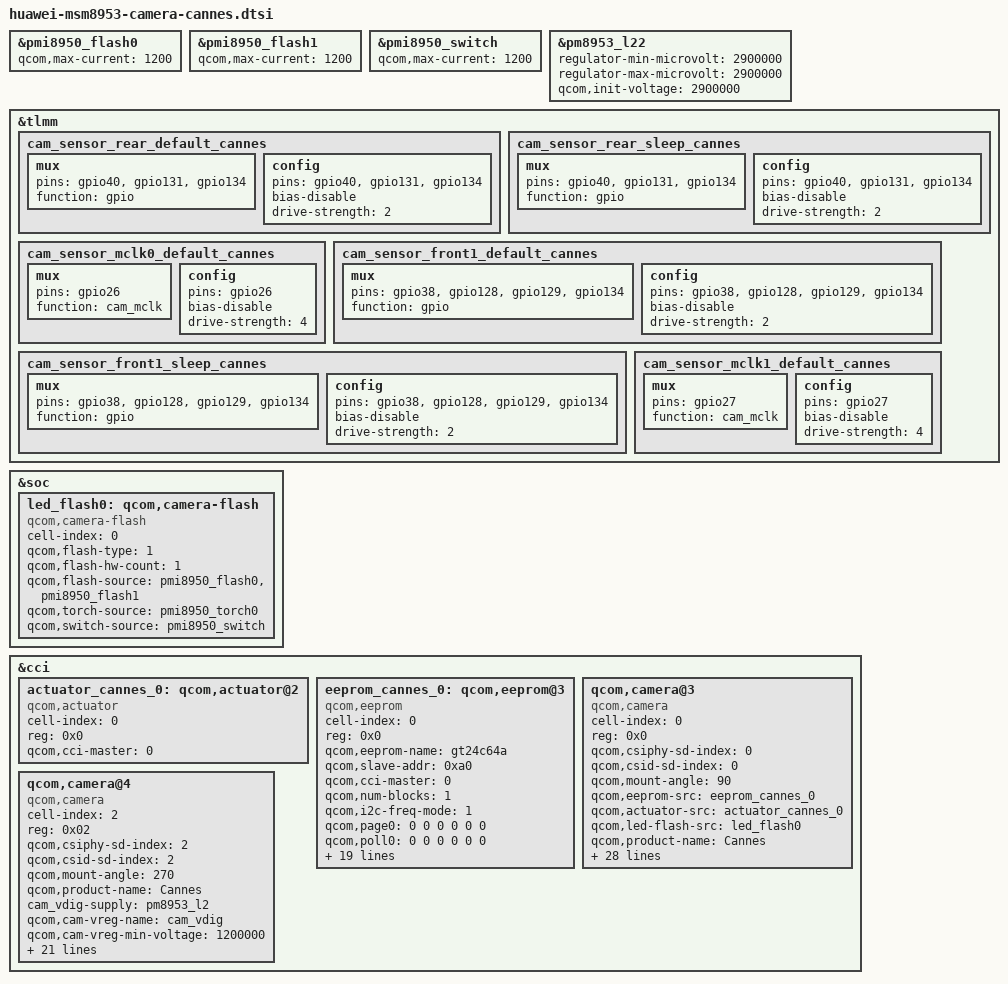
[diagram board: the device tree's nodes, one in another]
/*
 * Copyright (c) 2015, The Linux Foundation. All rights reserved.
 *
 * This program is free software; you can redistribute it and/or modify
 * it under the terms of the GNU General Public License version 2 and
 * only version 2 as published by the Free Software Foundation.
 *
 * This program is distributed in the hope that it will be useful,
 * but WITHOUT ANY WARRANTY; without even the implied warranty of
 * MERCHANTABILITY or FITNESS FOR A PARTICULAR PURPOSE.  See the
 * GNU General Public License for more details.
 */
&pmi8950_flash0 {
	qcom,max-current = <1200>;
};
&pmi8950_flash1 {
	qcom,max-current = <1200>;
};
&pmi8950_switch {
	qcom,max-current = <1200>;
};

&pm8953_l22 {
	regulator-min-microvolt = <2900000>;
	regulator-max-microvolt = <2900000>;
	qcom,init-voltage = <2900000>;
};

&tlmm {
	cam_sensor_rear_default_cannes: cam_sensor_rear_default_cannes{
		/* reset, cam_id, af_pwdm,ldo-vio*/
		mux {
			pins = "gpio40","gpio131","gpio134";
			function = "gpio";
		};

		config {
			pins = "gpio40","gpio131","gpio134";
			bias-disable; /* No PULL */
			drive-strength = <2>; /* 2 MA */
		};
	};

	cam_sensor_rear_sleep_cannes: cam_sensor_rear_sleep_cannes{
		/* reset, cam_id, af_pwdm, vio*/
		mux {
			pins = "gpio40","gpio131","gpio134";
			function = "gpio";
		};

		config {
			pins = "gpio40","gpio131","gpio134";
			bias-disable; /* No PULL */
			drive-strength = <2>; /* 2 MA */
		};
	};
	cam_sensor_mclk0_default_cannes: cam_sensor_mclk0_default_cannes {
		/* MCLK0 */
		mux {
			/* CLK, DATA */
			pins = "gpio26";
			function = "cam_mclk";
	};
		config {
			pins = "gpio26";
			bias-disable; /* No PULL */
			drive-strength = <4>; /* 4 MA */
		};
	};

	cam_sensor_front1_default_cannes: cam_sensor_front1_default_cannes{
		/* cam_id, vana, reset, vio */
		mux {
			pins = "gpio38", "gpio128", "gpio129", "gpio134";
			function = "gpio";
		};

		config {
			pins = "gpio38", "gpio128", "gpio129", "gpio134";
			bias-disable; /* No PULL */
			drive-strength = <2>; /* 2 MA */
		};
	};
	cam_sensor_front1_sleep_cannes: cam_sensor_front1_sleep_cannes{
		/* cam_id, vana, reset, vio */
		mux {
			pins = "gpio38", "gpio128", "gpio129", "gpio134";
			function = "gpio";
		};

		config {
			pins = "gpio38", "gpio128", "gpio129", "gpio134";
			bias-disable; /* No PULL */
			drive-strength = <2>; /* 2 MA */
		};
	};
	cam_sensor_mclk1_default_cannes:cam_sensor_mclk1_default_cannes{
		/* MCLK1 */
		mux {
			/* CLK, DATA */
			pins = "gpio27";
			function = "cam_mclk";
		};

		config {
			pins = "gpio27";
			bias-disable; /* No PULL */
			drive-strength = <4>; /* 4 MA */
		};
	};
};

&soc {
	/delete-node/ qcom,camera-flash;
	led_flash0: qcom,camera-flash {
		cell-index = <0>;
		compatible = "qcom,camera-flash";
		qcom,flash-type = <1>;
		qcom,flash-hw-count = <1>;
		qcom,flash-source = <&pmi8950_flash0 &pmi8950_flash1>;
		qcom,torch-source = <&pmi8950_torch0>;
		qcom,switch-source = <&pmi8950_switch>;
		status = "ok";
	};
};

&cci {
	/*delete qcom default node in msm8953-camera-sensor-mtp.dtsi*/
	/delete-node/ qcom,actuator@0;
	/delete-node/ qcom,actuator@1;
	/delete-node/ qcom,eeprom@0;
	/delete-node/ qcom,eeprom@1;
        /delete-node/ qcom,eeprom@2;
	/delete-node/ qcom,camera@0;
	/delete-node/ qcom,camera@1;
	/delete-node/ qcom,camera@2;

	actuator_cannes_0: qcom,actuator@2 {
		cell-index = <0>;
		reg = <0x0>;
		compatible = "qcom,actuator";
		qcom,cci-master = <0>;
	};

	eeprom_cannes_0: qcom,eeprom@3 {
		cell-index = <0>;
		reg = <0x0>;
		qcom,eeprom-name = "gt24c64a";
		compatible = "qcom,eeprom";
		qcom,slave-addr = <0xa0>;
		qcom,cci-master = <0>;
		qcom,num-blocks = <1>;
		qcom,i2c-freq-mode = <1>;

		qcom,page0 = <0 0 0 0 0 0>;
		qcom,poll0 = <0 0 0 0 0 0>;
		qcom,saddr0 = <0xa0>;
		qcom,mem0 = <7524 0x00 2 0 1 0>;


		cam_vana-supply = <&pm8953_l22>;
		qcom,cam-vreg-name = "cam_vana";
		qcom,cam-vreg-min-voltage = <2900000>;
		qcom,cam-vreg-max-voltage = <2900000>;
		qcom,cam-vreg-op-mode = <80000>;

		gpios = <&tlmm 40 0>,
		<&tlmm 134 0>;
		qcom,gpio-reset = <0>;
		qcom,gpio-vio = <1>;
		qcom,gpio-req-tbl-num = <0 1>;
		qcom,gpio-req-tbl-flags = <0 0>;
		qcom,gpio-req-tbl-label = "CAM_RESET0","CAM_VIO0";
		qcom,cam-power-seq-type = "sensor_vreg","sensor_gpio","sensor_gpio";
		qcom,cam-power-seq-val = "cam_vana","sensor_gpio_reset","sensor_gpio_vio";
		qcom,cam-power-seq-cfg-val = <1 0 1>;
		qcom,cam-power-seq-delay = <5 5 5>;
		status = "ok";
	};

	qcom,camera@3 {
		cell-index = <0>;
		compatible = "qcom,camera";
		reg = <0x0>;
		qcom,csiphy-sd-index = <0>;
		qcom,csid-sd-index = <0>;
		qcom,mount-angle = <90>;
		qcom,eeprom-src = <&eeprom_cannes_0>;
		qcom,actuator-src = <&actuator_cannes_0>;
		qcom,led-flash-src = <&led_flash0>;
		qcom,product-name = "Cannes";
		cam_vdig-supply = <&pm8953_l23>;
		cam_vaf-supply = <&pm8953_l17>;
		cam_vana-supply = <&pm8953_l22>;
		qcom,cam-vreg-name = "cam_vdig","cam_vaf", "cam_vana";
		qcom,cam-vreg-min-voltage = <1200000 2850000 2900000>;
		qcom,cam-vreg-max-voltage = <1200000 2850000 2900000>;
		qcom,cam-vreg-op-mode = <105000 100000 80000>;
		pinctrl-names = "cam_default", "cam_suspend";
		pinctrl-0 = <&cam_sensor_mclk0_default_cannes &cam_sensor_rear_default_cannes>;
		pinctrl-1 = <&cam_sensor_mclk0_sleep &cam_sensor_rear_sleep_cannes>;
		gpios = <&tlmm 26 0>,
			<&tlmm 131 0>,
			<&tlmm 40 0>,
			<&tlmm 134 0>;
		qcom,gpio-af-pwdm = <1>;
		qcom,gpio-reset = <2>;
		qcom,gpio-vio = <3>;
		qcom,gpio-req-tbl-num = <0 1 2 3>;
		qcom,gpio-req-tbl-flags = <1 0 0 0>;
		qcom,gpio-req-tbl-label = "CAMIF_MCLK0",
			"CAM_AF_PWD0",
			"CAM_RESET0",
			"CAM_VIO0";
		qcom,sensor-position = <0>;
		qcom,sensor-mode = <0>;
		qcom,cci-master = <0>;
		status = "ok";
		clocks = <&clock_gcc clk_mclk0_clk_src>,
				<&clock_gcc clk_gcc_camss_mclk0_clk>;
		clock-names = "cam_src_clk", "cam_clk";
		qcom,clock-rates = <24000000 0>;
	};

	qcom,camera@4 {
		cell-index = <2>;
		compatible = "qcom,camera";
		reg = <0x02>;
		qcom,csiphy-sd-index = <2>;
		qcom,csid-sd-index = <2>;
		qcom,mount-angle = <270>;
		qcom,product-name = "Cannes";
		cam_vdig-supply = <&pm8953_l2>;
		qcom,cam-vreg-name = "cam_vdig";
		qcom,cam-vreg-min-voltage = <1200000>;
		qcom,cam-vreg-max-voltage = <1200000>;
		qcom,cam-vreg-op-mode = <200000>;
		qcom,gpio-no-mux = <0>;
		pinctrl-names = "cam_default", "cam_suspend";
		pinctrl-0 = <&cam_sensor_mclk1_default_cannes &cam_sensor_front1_default_cannes>;
		pinctrl-1 = <&cam_sensor_mclk1_sleep &cam_sensor_front1_sleep_cannes>;
		gpios = <&tlmm 27 0>,
			<&tlmm 129 0>,
			<&tlmm 128 0>,
			<&tlmm 134 0>;
		qcom,gpio-reset = <1>;
		qcom,gpio-vana = <2>;
		qcom,gpio-vio = <3>;
		qcom,gpio-req-tbl-num = <0 1 2 3>;
		qcom,gpio-req-tbl-flags = <1 0 0 0>;
		qcom,gpio-req-tbl-label = "CAMIF_MCLK2",
			"CAM_RESET2",
			"CAM_AVDD2",
			"CAM_VIO2";
		qcom,sensor-position = <1>;
		qcom,sensor-mode = <0>;
		qcom,cci-master = <1>;
		clocks = <&clock_gcc clk_mclk1_clk_src>,
			<&clock_gcc clk_gcc_camss_mclk1_clk>;
		clock-names = "cam_src_clk", "cam_clk";
		qcom,clock-rates = <24000000 0>;
		status = "ok";
	};
};
